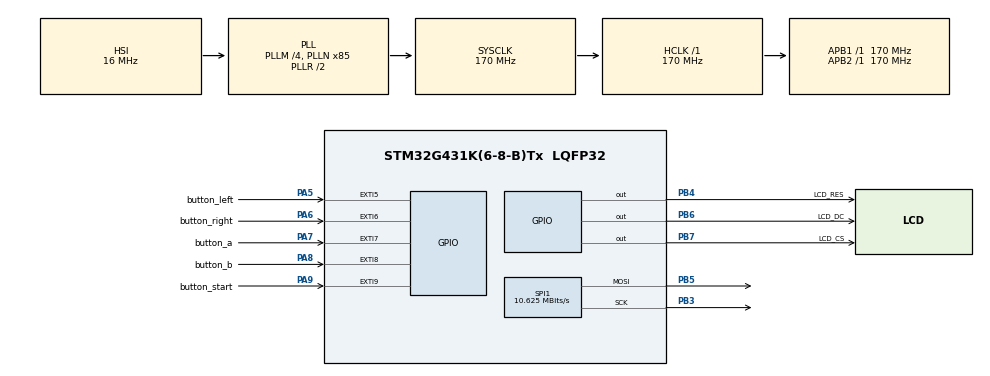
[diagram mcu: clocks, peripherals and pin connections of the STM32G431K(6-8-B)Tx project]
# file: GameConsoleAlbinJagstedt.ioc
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Dma.Request0=SPI1_TX
Dma.SPI1_TX.0.Direction=DMA_MEMORY_TO_PERIPH
Dma.SPI1_TX.0.EventEnable=DISABLE
Dma.SPI1_TX.0.Instance=DMA1_Channel2
Dma.SPI1_TX.0.MemDataAlignment=DMA_MDATAALIGN_BYTE
Dma.SPI1_TX.0.MemInc=DMA_MINC_ENABLE
Dma.SPI1_TX.0.Mode=DMA_NORMAL
Dma.SPI1_TX.0.PeriphDataAlignment=DMA_PDATAALIGN_BYTE
Dma.SPI1_TX.0.PeriphInc=DMA_PINC_DISABLE
Dma.SPI1_TX.0.Polarity=HAL_DMAMUX_REQ_GEN_RISING
Dma.SPI1_TX.0.Priority=DMA_PRIORITY_LOW
Dma.SPI1_TX.0.RequestNumber=1
Dma.SPI1_TX.0.SignalID=NONE
Dma.SPI1_TX.0.SyncEnable=DISABLE
Dma.SPI1_TX.0.SyncPolarity=HAL_DMAMUX_SYNC_NO_EVENT
Dma.SPI1_TX.0.SyncRequestNumber=1
Dma.SPI1_TX.0.SyncSignalID=NONE
Mcu.Family=STM32G4
Mcu.Name=STM32G431K(6-8-B)Tx
Mcu.Package=LQFP32
NUCLEO-G431KB.LD2=true
NUCLEO-G431KB.VCP=true
NVIC.DMA1_Channel2_IRQn=true\:0\:0\:false\:false\:true\:false\:true\:true
NVIC.EXTI9_5_IRQn=true\:0\:0\:false\:false\:true\:true\:true\:true
NVIC.PriorityGroup=NVIC_PRIORITYGROUP_4
NVIC.TIM6_DAC_IRQn=true\:0\:0\:false\:false\:true\:true\:true\:true
PA13.GPIO_Label=T_SWDIO
PA13.Signal=SYS_JTMS-SWDIO
PA14.GPIO_Label=T_SWCLK
PA14.Signal=SYS_JTCK-SWCLK
PA2.Signal=USART2_TX
PA3.Signal=USART2_RX
PA5.GPIO_Label=button_left
PA5.GPIO_ModeDefaultEXTI=GPIO_MODE_IT_FALLING
PA5.GPIO_PuPd=GPIO_PULLUP
PA5.Signal=GPXTI5
PA6.GPIO_Label=button_right
PA6.GPIO_ModeDefaultEXTI=GPIO_MODE_IT_FALLING
PA6.GPIO_PuPd=GPIO_PULLUP
PA6.Signal=GPXTI6
PA7.GPIO_Label=button_a
PA7.GPIO_ModeDefaultEXTI=GPIO_MODE_IT_FALLING
PA7.GPIO_PuPd=GPIO_PULLUP
PA7.Signal=GPXTI7
PA8.GPIO_Label=button_b
PA8.GPIO_ModeDefaultEXTI=GPIO_MODE_IT_FALLING
PA8.GPIO_PuPd=GPIO_PULLUP
PA8.Signal=GPXTI8
PA9.GPIO_Label=button_start
PA9.GPIO_ModeDefaultEXTI=GPIO_MODE_IT_FALLING
PA9.GPIO_PuPd=GPIO_PULLUP
PA9.Signal=GPXTI9
PB3.Mode=TX_Only_Simplex_Unidirect_Master
PB3.Signal=SPI1_SCK
PB4.GPIO_Label=LCD_RES
PB4.Signal=GPIO_Output
PB5.Mode=TX_Only_Simplex_Unidirect_Master
PB5.Signal=SPI1_MOSI
PB6.GPIO_Label=LCD_DC
PB6.Signal=GPIO_Output
PB7.GPIO_Label=LCD_CS
PB7.Signal=GPIO_Output
ProjectManager.HeapSize=0x200
ProjectManager.StackSize=0x400
ProjectManager.TargetToolchain=STM32CubeIDE
RCC.ADC12Freq_Value=170000000
RCC.AHBFreq_Value=170000000
RCC.APB1Freq_Value=170000000
RCC.APB1TimFreq_Value=170000000
RCC.APB2Freq_Value=170000000
RCC.APB2TimFreq_Value=170000000
RCC.CortexFreq_Value=170000000
RCC.EXTERNAL_CLOCK_VALUE=12288000
RCC.HCLKFreq_Value=170000000
RCC.HSE_VALUE=8000000
RCC.HSI48_VALUE=48000000
RCC.HSI_VALUE=16000000
RCC.LSE_VALUE=32768
RCC.PLLM=RCC_PLLM_DIV4
RCC.PLLN=85
RCC.SYSCLKFreq_VALUE=170000000
RCC.SYSCLKSource=RCC_SYSCLKSOURCE_PLLCLK
RCC.USBFreq_Value=170000000
RCC.VCOOutputFreq_Value=340000000
SPI1.BaudRatePrescaler=SPI_BAUDRATEPRESCALER_16
SPI1.CalculateBaudRate=10.625 MBits/s
SPI1.DataSize=SPI_DATASIZE_8BIT
SPI1.Direction=SPI_DIRECTION_2LINES
SPI1.Mode=SPI_MODE_MASTER
SPI1.NSSPMode=SPI_NSS_PULSE_DISABLE
SPI1.VirtualType=VM_MASTER
TIM6.PeriodNoDither=1699
TIM6.Prescaler=999
VP_NUCLEO-G431KB_VS_BSP_COMMON.Mode=COMMON
VP_SYS_VS_DBSignals.Mode=DisableDeadBatterySignals
VP_TIM6_VS_ClockSourceINT.Mode=Enable_Timer
board=NUCLEO-G431KB

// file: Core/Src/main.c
/* USER CODE BEGIN Header */
/**
  ******************************************************************************
  * @file           : main.c
  * @brief          : Main program body
  ******************************************************************************
  * @attention
  *
  * Copyright (c) 2026 STMicroelectronics.
  * All rights reserved.
  *
  * This software is licensed under terms that can be found in the LICENSE file
  * in the root directory of this software component.
  * If no LICENSE file comes with this software, it is provided AS-IS.
  *
  ******************************************************************************
  */
/* USER CODE END Header */
#include "main.h"

/* USER CODE BEGIN Includes */

#include "st7735.h"

/* USER CODE END Includes */

COM_InitTypeDef BspCOMInit;

SPI_HandleTypeDef hspi1;
DMA_HandleTypeDef hdma_spi1_tx;

TIM_HandleTypeDef htim6;

void SystemClock_Config(void);
static void MX_GPIO_Init(void);
static void MX_DMA_Init(void);
static void MX_TIM6_Init(void);
static void MX_SPI1_Init(void);

int main(void)
{

  /* MCU Configuration--------------------------------------------------------*/

  /* Reset of all peripherals, Initializes the Flash interface and the Systick. */
  HAL_Init();

  /* Configure the system clock */
  SystemClock_Config();

  /* Initialize all configured peripherals */
  MX_GPIO_Init();
  MX_DMA_Init();
  MX_TIM6_Init();
  MX_SPI1_Init();
  /* USER CODE BEGIN 2 */

  ST7735_init();
  HAL_TIM_Base_Start_IT(&htim6);

  uint16_t x0 = 0;
  uint16_t y0 = 40;
  uint16_t w  = 128;
  uint16_t h  = 80;

  ST7735_fill_screen(ST7735_BLACK);
  ST7735_fill_rect(x0, y0, w, h, 0x0354);
  ST7735_fill_rect(x0 + 40, y0, 16, h, 0xFE60);
  ST7735_fill_rect(x0, y0 + 32, w, 16, 0xFE60);

  /* USER CODE END 2 */

  /* Initialize leds */
  BSP_LED_Init(LED_GREEN);

  /* Initialize COM1 port (115200, 8 bits (7-bit data + 1 stop bit), no parity */
  BspCOMInit.BaudRate   = 115200;
  BspCOMInit.WordLength = COM_WORDLENGTH_8B;
  BspCOMInit.StopBits   = COM_STOPBITS_1;
  BspCOMInit.Parity     = COM_PARITY_NONE;
  BspCOMInit.HwFlowCtl  = COM_HWCONTROL_NONE;
  if (BSP_COM_Init(COM1, &BspCOMInit) != BSP_ERROR_NONE)
  {
    Error_Handler();
  }

  /* Infinite loop */
  while (1)
  {

  }
}

void SystemClock_Config(void)
{
  RCC_OscInitTypeDef RCC_OscInitStruct = {0};
  RCC_ClkInitTypeDef RCC_ClkInitStruct = {0};

  /** Configure the main internal regulator output voltage
  */
  HAL_PWREx_ControlVoltageScaling(PWR_REGULATOR_VOLTAGE_SCALE1_BOOST);

  /** Initializes the RCC Oscillators according to the specified parameters
  * in the RCC_OscInitTypeDef structure.
  */
  RCC_OscInitStruct.OscillatorType = RCC_OSCILLATORTYPE_HSI;
  RCC_OscInitStruct.HSIState = RCC_HSI_ON;
  RCC_OscInitStruct.HSICalibrationValue = RCC_HSICALIBRATION_DEFAULT;
  RCC_OscInitStruct.PLL.PLLState = RCC_PLL_ON;
  RCC_OscInitStruct.PLL.PLLSource = RCC_PLLSOURCE_HSI;
  RCC_OscInitStruct.PLL.PLLM = RCC_PLLM_DIV4;
  RCC_OscInitStruct.PLL.PLLN = 85;
  RCC_OscInitStruct.PLL.PLLP = RCC_PLLP_DIV2;
  RCC_OscInitStruct.PLL.PLLQ = RCC_PLLQ_DIV2;
  RCC_OscInitStruct.PLL.PLLR = RCC_PLLR_DIV2;
  if (HAL_RCC_OscConfig(&RCC_OscInitStruct) != HAL_OK)
  {
    Error_Handler();
  }

  /** Initializes the CPU, AHB and APB buses clocks
  */
  RCC_ClkInitStruct.ClockType = RCC_CLOCKTYPE_HCLK|RCC_CLOCKTYPE_SYSCLK
                              |RCC_CLOCKTYPE_PCLK1|RCC_CLOCKTYPE_PCLK2;
  RCC_ClkInitStruct.SYSCLKSource = RCC_SYSCLKSOURCE_PLLCLK;
  RCC_ClkInitStruct.AHBCLKDivider = RCC_SYSCLK_DIV1;
  RCC_ClkInitStruct.APB1CLKDivider = RCC_HCLK_DIV1;
  RCC_ClkInitStruct.APB2CLKDivider = RCC_HCLK_DIV1;

  if (HAL_RCC_ClockConfig(&RCC_ClkInitStruct, FLASH_LATENCY_4) != HAL_OK)
  {
    Error_Handler();
  }
}

static void MX_SPI1_Init(void)
{

  /* SPI1 parameter configuration*/
  hspi1.Instance = SPI1;
  hspi1.Init.Mode = SPI_MODE_MASTER;
  hspi1.Init.Direction = SPI_DIRECTION_2LINES;
  hspi1.Init.DataSize = SPI_DATASIZE_8BIT;
  hspi1.Init.CLKPolarity = SPI_POLARITY_LOW;
  hspi1.Init.CLKPhase = SPI_PHASE_1EDGE;
  hspi1.Init.NSS = SPI_NSS_SOFT;
  hspi1.Init.BaudRatePrescaler = SPI_BAUDRATEPRESCALER_16;
  hspi1.Init.FirstBit = SPI_FIRSTBIT_MSB;
  hspi1.Init.TIMode = SPI_TIMODE_DISABLE;
  hspi1.Init.CRCCalculation = SPI_CRCCALCULATION_DISABLE;
  hspi1.Init.CRCPolynomial = 7;
  hspi1.Init.CRCLength = SPI_CRC_LENGTH_DATASIZE;
  hspi1.Init.NSSPMode = SPI_NSS_PULSE_DISABLE;
  if (HAL_SPI_Init(&hspi1) != HAL_OK)
  {
    Error_Handler();
  }

}

static void MX_TIM6_Init(void)
{

  TIM_MasterConfigTypeDef sMasterConfig = {0};

  htim6.Instance = TIM6;
  htim6.Init.Prescaler = 999;
  htim6.Init.CounterMode = TIM_COUNTERMODE_UP;
  htim6.Init.Period = 1699;
  htim6.Init.AutoReloadPreload = TIM_AUTORELOAD_PRELOAD_DISABLE;
  if (HAL_TIM_Base_Init(&htim6) != HAL_OK)
  {
    Error_Handler();
  }
  sMasterConfig.MasterOutputTrigger = TIM_TRGO_RESET;
  sMasterConfig.MasterSlaveMode = TIM_MASTERSLAVEMODE_DISABLE;
  if (HAL_TIMEx_MasterConfigSynchronization(&htim6, &sMasterConfig) != HAL_OK)
  {
    Error_Handler();
  }

}

static void MX_DMA_Init(void)
{

  /* DMA controller clock enable */
  __HAL_RCC_DMAMUX1_CLK_ENABLE();
  __HAL_RCC_DMA1_CLK_ENABLE();

  /* DMA interrupt init */
  /* DMA1_Channel2_IRQn interrupt configuration */
  HAL_NVIC_SetPriority(DMA1_Channel2_IRQn, 0, 0);
  HAL_NVIC_EnableIRQ(DMA1_Channel2_IRQn);

}

static void MX_GPIO_Init(void)
{
  GPIO_InitTypeDef GPIO_InitStruct = {0};

  /* GPIO Ports Clock Enable */
  __HAL_RCC_GPIOA_CLK_ENABLE();
  __HAL_RCC_GPIOB_CLK_ENABLE();

  /*Configure GPIO pin Output Level */
  HAL_GPIO_WritePin(GPIOB, LCD_RES_Pin|LCD_DC_Pin|LCD_CS_Pin, GPIO_PIN_RESET);

  /*Configure GPIO pins : button_left_Pin button_right_Pin button_a_Pin button_b_Pin
                           button_start_Pin */
  GPIO_InitStruct.Pin = button_left_Pin|button_right_Pin|button_a_Pin|button_b_Pin
                          |button_start_Pin;
  GPIO_InitStruct.Mode = GPIO_MODE_IT_FALLING;
  GPIO_InitStruct.Pull = GPIO_PULLUP;
  HAL_GPIO_Init(GPIOA, &GPIO_InitStruct);

  /*Configure GPIO pins : LCD_RES_Pin LCD_DC_Pin LCD_CS_Pin */
  GPIO_InitStruct.Pin = LCD_RES_Pin|LCD_DC_Pin|LCD_CS_Pin;
  GPIO_InitStruct.Mode = GPIO_MODE_OUTPUT_PP;
  GPIO_InitStruct.Pull = GPIO_NOPULL;
  GPIO_InitStruct.Speed = GPIO_SPEED_FREQ_LOW;
  HAL_GPIO_Init(GPIOB, &GPIO_InitStruct);

  /* EXTI interrupt init*/
  HAL_NVIC_SetPriority(EXTI9_5_IRQn, 0, 0);
  HAL_NVIC_EnableIRQ(EXTI9_5_IRQn);

}

/* USER CODE BEGIN Header */
/**
  ******************************************************************************
  * @file           : main.c
  * @brief          : Main program body
  ******************************************************************************
  * @attention
  *
  * Copyright (c) 2026 STMicroelectronics.
  * All rights reserved.
  *
  * This software is licensed under terms that can be found in the LICENSE file
  * in the root directory of this software component.
  * If no LICENSE file comes with this software, it is provided AS-IS.
  *
  ******************************************************************************
  */
/* USER CODE END Header */

void Error_Handler(void)
{
  __disable_irq();
  while (1)
  {
  }
}
